VERSION ""

NS_ :

BS_:

BU_:

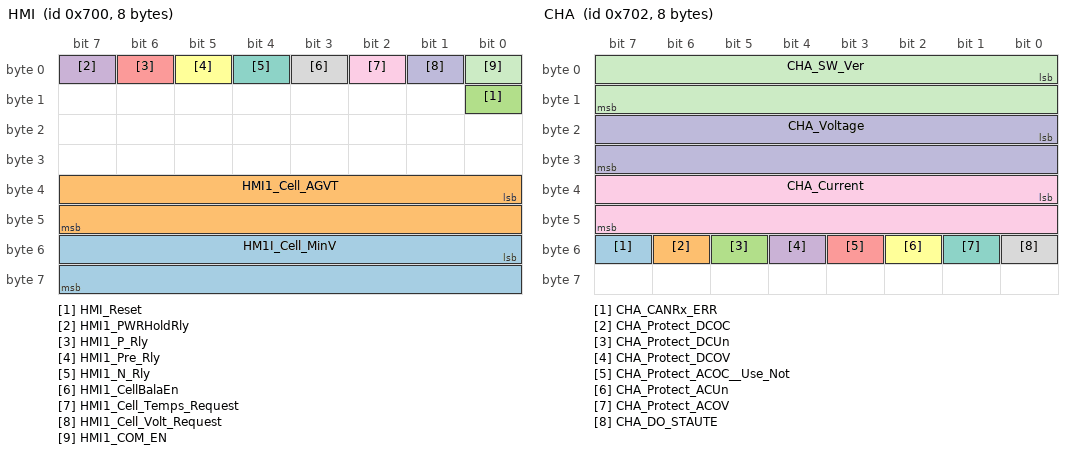
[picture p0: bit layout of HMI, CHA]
BO_ 1792 HMI: 8 Vector__XXX
 SG_ HM1I_Cell_MinV : 48|16@1+ (0.001,0.0) [0.0|4.5] "V" Vector__XXX
 SG_ HMI1_Cell_AGVT : 32|16@1+ (0.1,0.0) [-30.0|100.0] "deg" Vector__XXX
 SG_ HMI_Reset : 8|1@1+ (1.0,0.0) [0.0|1.0] "F" Vector__XXX
 SG_ HMI1_PWRHoldRly : 7|1@1+ (1.0,0.0) [0.0|1.0] "F" Vector__XXX
 SG_ HMI1_P_Rly : 6|1@1+ (1.0,0.0) [0.0|1.0] "F" Vector__XXX
 SG_ HMI1_Pre_Rly : 5|1@1+ (1.0,0.0) [0.0|1.0] "F" Vector__XXX
 SG_ HMI1_N_Rly : 4|1@1+ (1.0,0.0) [0.0|1.0] "F" Vector__XXX
 SG_ HMI1_CellBalaEn : 3|1@1+ (1.0,0.0) [0.0|1.0] "F" Vector__XXX
 SG_ HMI1_Cell_Temps_Request : 2|1@1+ (1.0,0.0) [0.0|1.0] "F" Vector__XXX
 SG_ HMI1_Cell_Volt_Request : 1|1@1+ (1.0,0.0) [0.0|1.0] "F" Vector__XXX
 SG_ HMI1_COM_EN : 0|1@1+ (1.0,0.0) [0.0|1.0] "F" Vector__XXX

BO_ 1794 CHA: 8 Vector__XXX
 SG_ CHA_CANRx_ERR : 55|1@1+ (1.0,0.0) [0.0|1.0] "F" Vector__XXX
 SG_ CHA_Protect_DCOC : 54|1@1+ (1.0,0.0) [0.0|1.0] "F" Vector__XXX
 SG_ CHA_Protect_DCUn : 53|1@1+ (1.0,0.0) [0.0|1.0] "F" Vector__XXX
 SG_ CHA_Protect_DCOV : 52|1@1+ (1.0,0.0) [0.0|1.0] "F" Vector__XXX
 SG_ CHA_Protect_ACOC__Use_Not : 51|1@1+ (1.0,0.0) [0.0|1.0] "F" Vector__XXX
 SG_ CHA_Protect_ACUn : 50|1@1+ (1.0,0.0) [0.0|1.0] "F" Vector__XXX
 SG_ CHA_Protect_ACOV : 49|1@1+ (1.0,0.0) [0.0|1.0] "F" Vector__XXX
 SG_ CHA_DO_STAUTE : 48|1@1+ (1.0,0.0) [0.0|1.0] "F" Vector__XXX
 SG_ CHA_Current : 32|16@1- (0.1,0.0) [0.0|100.0] "A" Vector__XXX
 SG_ CHA_Voltage : 16|16@1+ (0.1,0.0) [40.0|100.0] "V" Vector__XXX
 SG_ CHA_SW_Ver : 0|16@1+ (0.1,0.0) [1.0|99.0] "VER" Vector__XXX

BO_ 1536 VCU_RE: 8 Vector__XXX
 SG_ Ifcu_BSAHldShutdown : 9|1@1+ (1.0,0.0) [0.0|1.0] "F" Vector__XXX
 SG_ Ifcu_BSAReset : 8|1@1+ (1.0,0.0) [0.0|1.0] "F" Vector__XXX

BO_ 812 CT_Sensor: 8 Vector__XXX
 SG_ CT_Sensor : 0|16@1+ (0.1,0.0) [-500.0|500.0] "A" Vector__XXX

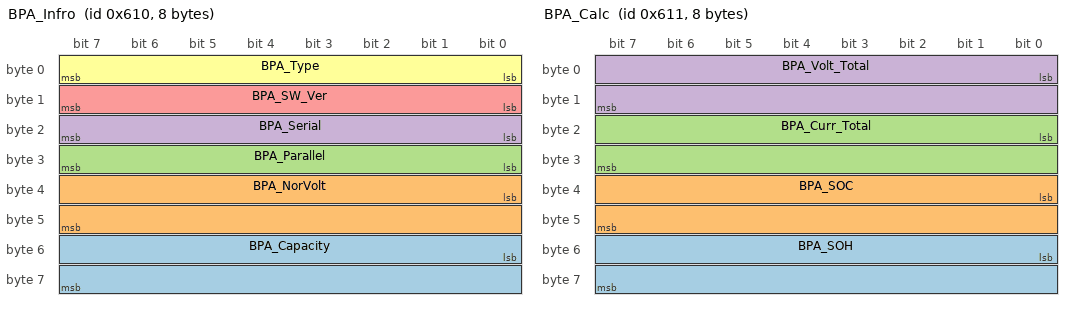
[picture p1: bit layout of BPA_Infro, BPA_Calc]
BO_ 1552 BPA_Infro: 8 Vector__XXX
 SG_ BPA_Capacity : 48|16@1+ (0.1,0.0) [0.0|500.0] "Ah" Vector__XXX
 SG_ BPA_NorVolt : 32|16@1+ (0.1,0.0) [0.0|900.0] "V" Vector__XXX
 SG_ BPA_Parallel : 24|8@1+ (1.0,0.0) [0.0|255.0] "P" Vector__XXX
 SG_ BPA_Serial : 16|8@1+ (1.0,0.0) [0.0|255.0] "S" Vector__XXX
 SG_ BPA_SW_Ver : 8|8@1+ (1.0,0.0) [0.0|255.0] "VER" Vector__XXX
 SG_ BPA_Type : 0|8@1+ (1.0,0.0) [0.0|255.0] "Type" Vector__XXX

BO_ 1553 BPA_Calc: 8 Vector__XXX
 SG_ BPA_SOH : 48|16@1+ (0.1,0.0) [0.0|100.0] "%" Vector__XXX
 SG_ BPA_SOC : 32|16@1+ (0.1,0.0) [0.0|100.0] "%" Vector__XXX
 SG_ BPA_Curr_Total : 16|16@1+ (0.1,0.0) [-500.0|500.0] "A" Vector__XXX
 SG_ BPA_Volt_Total : 0|16@1+ (0.1,0.0) [0.0|900.0] "V" Vector__XXX

BO_ 1554 BPA_State: 8 Vector__XXX
 SG_ Sys_CANCOMEnable : 60|1@1+ (1.0,0.0) [0.0|1.0] "F" Vector__XXX
 SG_ Sys_CellTempsOk : 59|1@1+ (1.0,0.0) [0.0|1.0] "F" Vector__XXX
 SG_ Sys_CellVoltOk : 58|1@1+ (1.0,0.0) [0.0|1.0] "F" Vector__XXX
 SG_ Sys_ISOSPICOMERR : 57|1@1+ (1.0,0.0) [0.0|1.0] "F" Vector__XXX
 SG_ Sys_CANCOMERR : 56|1@1+ (1.0,0.0) [0.0|1.0] "F" Vector__XXX
 SG_ Sys_HMIBalanceMode : 55|1@1+ (1.0,0.0) [0.0|1.0] "F" Vector__XXX
 SG_ Sys_HMICOMEnable : 54|1@1+ (1.0,0.0) [0.0|1.0] "F" Vector__XXX
 SG_ Sys_RlyERR : 53|1@1+ (1.0,0.0) [0.0|1.0] "F" Vector__XXX
 SG_ Sys_MSDERR : 52|1@1+ (1.0,0.0) [0.0|1.0] "F" Vector__XXX
 SG_ Sys_PwrHoldRlyDOStatus : 51|1@1+ (1.0,0.0) [0.0|1.0] "F" Vector__XXX
 SG_ Sys_PreRlyDOStatus : 50|1@1+ (1.0,0.0) [0.0|1.0] "F" Vector__XXX
 SG_ Sys_PRlyDOStatus : 49|1@1+ (1.0,0.0) [0.0|1.0] "F" Vector__XXX
 SG_ Sys_NRlyDOStatus : 48|1@1+ (1.0,0.0) [0.0|1.0] "F" Vector__XXX
 SG_ Sys_Fault : 47|1@1+ (1.0,0.0) [0.0|1.0] "F" Vector__XXX
 SG_ Sys_Aalarm : 46|1@1+ (1.0,0.0) [0.0|1.0] "F" Vector__XXX
 SG_ Sys_DisCharMode : 45|1@1+ (1.0,0.0) [0.0|1.0] "F" Vector__XXX
 SG_ Sys_BalanceEn : 44|1@1+ (1.0,0.0) [0.0|1.0] "F" Vector__XXX
 SG_ Sys_BalaMode : 43|1@1+ (1.0,0.0) [0.0|1.0] "F" Vector__XXX
 SG_ Sys_SysSocMode : 42|1@1+ (1.0,0.0) [0.0|1.0] "F" Vector__XXX
 SG_ Sys_CellInforRead : 41|1@1+ (1.0,0.0) [0.0|1.0] "F" Vector__XXX
 SG_ Sys_INITOK : 40|1@1+ (1.0,0.0) [0.0|1.0] "F" Vector__XXX
 SG_ Sys_SocSeqState : 38|2@1+ (1.0,0.0) [0.0|3.0] "s" Vector__XXX
 SG_ SyS_RlySeqState : 35|3@1+ (1.0,0.0) [0.0|7.0] "S" Vector__XXX
 SG_ Sys_SysSeqState : 32|3@1+ (1.0,0.0) [0.0|7.0] "S" Vector__XXX
 SG_ BPA_ChargerEn : 21|1@1+ (1.0,0.0) [0.0|1.0] "F" Vector__XXX
 SG_ BPA_MSD_AUX : 20|1@1+ (1.0,0.0) [0.0|1.0] "F" Vector__XXX
 SG_ BPA_PreChar_Rly : 19|1@1+ (1.0,0.0) [0.0|1.0] "F" Vector__XXX
 SG_ BPA_Pos_Rly : 18|1@1+ (1.0,0.0) [0.0|1.0] "F" Vector__XXX
 SG_ BPA_Neg_Rly : 17|1@1+ (1.0,0.0) [0.0|1.0] "F" Vector__XXX
 SG_ BPA_Balance : 16|1@1+ (1.0,0.0) [0.0|1.0] "F" Vector__XXX
 SG_ BPA_Protect_Status : 8|8@1+ (1.0,0.0) [0.0|5.0] "P" Vector__XXX
 SG_ BPA_Divice_Status : 0|8@1+ (1.0,0.0) [0.0|5.0] "S" Vector__XXX

BO_ 1555 BPA_ProtectState: 8 Vector__XXX
 SG_ BPA_Prtct_ISORESIS_Err : 44|1@1+ (1.0,0.0) [0|0] "F" Vector__XXX
 SG_ BPA_Prtct_CT_COM_Err : 43|1@1+ (1.0,0.0) [0|0] "F" Vector__XXX
 SG_ BPA_Prtct_CAN_COM_Err : 42|1@1+ (1.0,0.0) [0|0] "F" Vector__XXX
 SG_ BPA_Prtct_ISOSPI_Err : 41|1@1+ (1.0,0.0) [0|0] "F" Vector__XXX
 SG_ BPA_Prtct_Rly_Err : 40|1@1+ (1.0,0.0) [0|0] "F" Vector__XXX
 SG_ BPA_Prtct_Charger_UnBPAWR : 39|1@1+ (1.0,0.0) [0|0] "F" Vector__XXX
 SG_ BPA_Prtct_Discharger_UnBPAWR : 38|1@1+ (1.0,0.0) [0|0] "F" Vector__XXX
 SG_ BPA_Prtct_Cell_UnbalT : 37|1@1+ (1.0,0.0) [0|0] "F" Vector__XXX
 SG_ BPA_Prtct_Charger_Cell_UT : 36|1@1+ (1.0,0.0) [0|0] "F" Vector__XXX
 SG_ BPA_Prtct_DisCharger_Cell_UT : 35|1@1+ (1.0,0.0) [0|0] "F" Vector__XXX
 SG_ BPA_Prtct_Charger_Cell_OT : 34|1@1+ (1.0,0.0) [0|0] "F" Vector__XXX
 SG_ BPA_Prtct_DisCharger_Cell_OT : 33|1@1+ (1.0,0.0) [0|0] "F" Vector__XXX
 SG_ BPA_Prtct_Cell_UnbalV : 32|1@1+ (1.0,0.0) [0|0] "F" Vector__XXX
 SG_ BPA_Prtct_Cell_UV : 31|1@1+ (1.0,0.0) [0|0] "F" Vector__XXX
 SG_ BPA_Prtct_Cell_OV : 30|1@1+ (1.0,0.0) [0|0] "F" Vector__XXX
 SG_ BPA_Prtct_UV : 29|1@1+ (1.0,0.0) [0|0] "F" Vector__XXX
 SG_ BPA_Prtct_OV : 28|1@1+ (1.0,0.0) [0|0] "F" Vector__XXX
 SG_ BPA_Prtct_SOC_Un : 27|1@1+ (1.0,0.0) [0|0] "F" Vector__XXX
 SG_ BPA_Prtct_SOC_OV : 26|1@1+ (1.0,0.0) [0|0] "F" Vector__XXX
 SG_ BPA_Prtct_Chager_OC : 25|1@1+ (1.0,0.0) [0|0] "F" Vector__XXX
 SG_ BPA_Prtct_Dischager_OC : 24|1@1+ (1.0,0.0) [0|0] "F" Vector__XXX
 SG_ BPA_Wn_Charger_UnBPAWR : 15|1@1+ (1.0,0.0) [0|0] "F" Vector__XXX
 SG_ BPA_Wn_Discharger_UnBPAWR : 14|1@1+ (1.0,0.0) [0|0] "F" Vector__XXX
 SG_ BSA_Wn_Cell_UnbalT : 13|1@1+ (1.0,0.0) [0|0] "F" Vector__XXX
 SG_ BPA_Wn_Charger_Cell_UT : 12|1@1+ (1.0,0.0) [0|0] "F" Vector__XXX
 SG_ BPA_Wn_DisCharger_Cell_UT : 11|1@1+ (1.0,0.0) [0|0] "F" Vector__XXX
 SG_ BPA_Wn_Charger_Cell_OT : 10|1@1+ (1.0,0.0) [0|0] "F" Vector__XXX
 SG_ BPA_Wn_DisCharger_Cell_OT : 9|1@1+ (1.0,0.0) [0|0] "F" Vector__XXX
 SG_ BPA_Wn_Cell_UnbalV : 8|1@1+ (1.0,0.0) [0|0] "F" Vector__XXX
 SG_ BPA_Wn_Cell_UV : 7|1@1+ (1.0,0.0) [0|0] "F" Vector__XXX
 SG_ BPA_Wn_Cell_OV : 6|1@1+ (1.0,0.0) [0|0] "F" Vector__XXX
 SG_ BPA_Wn_UV : 5|1@1+ (1.0,0.0) [0|0] "F" Vector__XXX
 SG_ BPA_Wn_OV : 4|1@1+ (1.0,0.0) [0|0] "F" Vector__XXX
 SG_ BPA_Wn_SOC_UV : 3|1@1+ (1.0,0.0) [0|0] "F" Vector__XXX
 SG_ BPA_Wn_SOC_OV : 2|1@1+ (1.0,0.0) [0|0] "F" Vector__XXX
 SG_ BPA_Wn_Chager_OC : 1|1@1+ (1.0,0.0) [0|0] "F" Vector__XXX
 SG_ BPA_Wn_Dischager_OC : 0|1@1+ (1.0,0.0) [0|0] "F" Vector__XXX

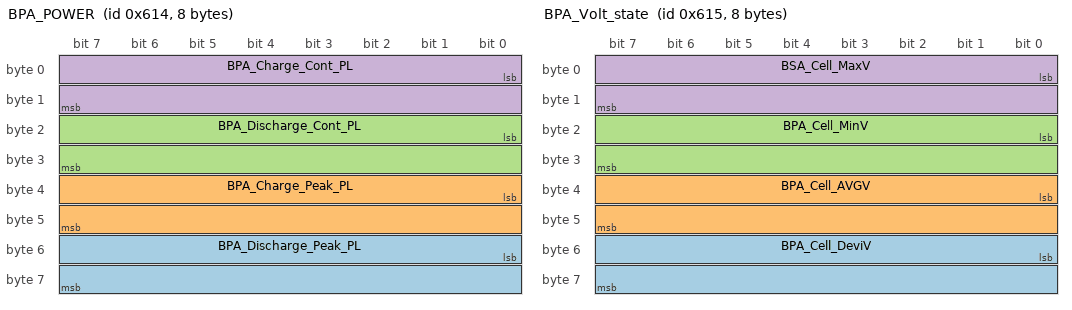
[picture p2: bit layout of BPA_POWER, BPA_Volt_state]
BO_ 1556 BPA_POWER: 8 Vector__XXX
 SG_ BPA_Discharge_Peak_PL : 48|16@1+ (0.1,0.0) [0.0|20.0] "kW" Vector__XXX
 SG_ BPA_Charge_Peak_PL : 32|16@1+ (0.1,0.0) [0.0|20.0] "kW" Vector__XXX
 SG_ BPA_Discharge_Cont_PL : 16|16@1+ (0.1,0.0) [0.0|20.0] "kW" Vector__XXX
 SG_ BPA_Charge_Cont_PL : 0|16@1+ (0.1,0.0) [0.0|20.0] "kW" Vector__XXX

BO_ 1557 BPA_Volt_state: 8 Vector__XXX
 SG_ BPA_Cell_DeviV : 48|16@1+ (1.0,0.0) [0.0|1000.0] "mV" Vector__XXX
 SG_ BPA_Cell_AVGV : 32|16@1+ (0.001,0.0) [0.0|4.5] "V" Vector__XXX
 SG_ BPA_Cell_MinV : 16|16@1+ (0.001,0.0) [0.0|4.5] "V" Vector__XXX
 SG_ BSA_Cell_MaxV : 0|16@1+ (0.001,0.0) [0.0|4.5] "V" Vector__XXX

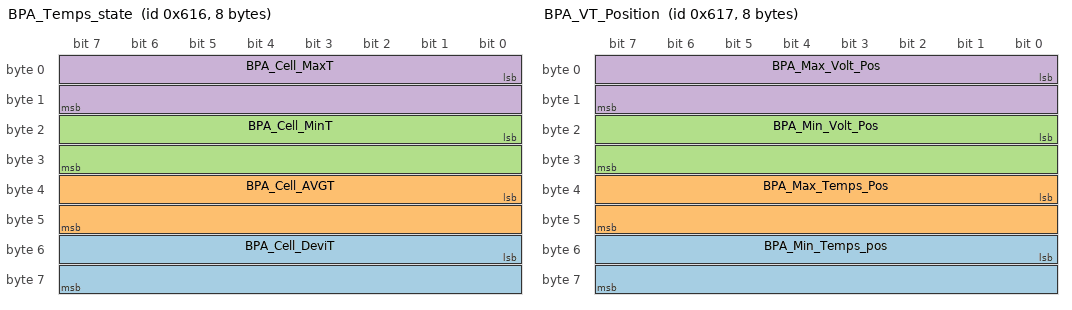
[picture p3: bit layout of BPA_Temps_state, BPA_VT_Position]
BO_ 1558 BPA_Temps_state: 8 Vector__XXX
 SG_ BPA_Cell_DeviT : 48|16@1+ (0.1,0.0) [0.0|100.0] "deg" Vector__XXX
 SG_ BPA_Cell_AVGT : 32|16@1+ (0.1,0.0) [-30.0|100.0] "deg" Vector__XXX
 SG_ BPA_Cell_MinT : 16|16@1+ (0.1,0.0) [-30.0|100.0] "deg" Vector__XXX
 SG_ BPA_Cell_MaxT : 0|16@1+ (0.1,0.0) [-30.0|100.0] "deg" Vector__XXX

BO_ 1559 BPA_VT_Position: 8 Vector__XXX
 SG_ BPA_Min_Temps_pos : 48|16@1+ (1.0,0.0) [0.0|200.0] "Pos" Vector__XXX
 SG_ BPA_Max_Temps_Pos : 32|16@1+ (1.0,0.0) [0.0|200.0] "Pos" Vector__XXX
 SG_ BPA_Min_Volt_Pos : 16|16@1+ (1.0,0.0) [0.0|200.0] "Pos" Vector__XXX
 SG_ BPA_Max_Volt_Pos : 0|16@1+ (1.0,0.0) [0.0|200.0] "Pos" Vector__XXX

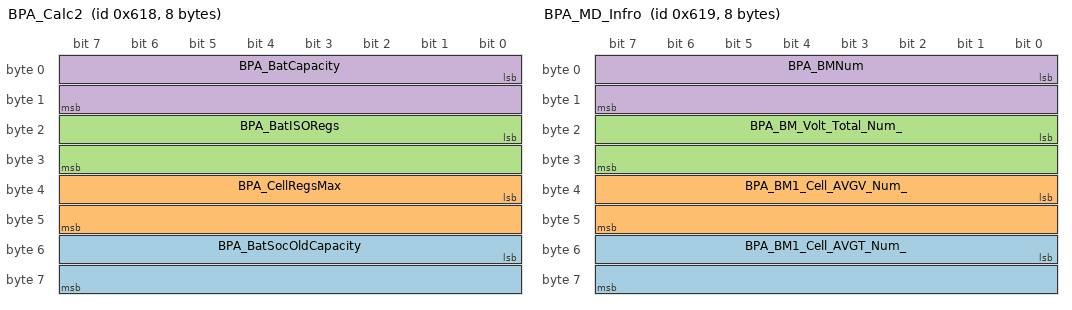
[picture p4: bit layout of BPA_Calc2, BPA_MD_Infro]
BO_ 1560 BPA_Calc2: 8 Vector__XXX
 SG_ BPA_BatSocOldCapacity : 48|16@1+ (0.1,0.0) [0.0|500.0] "Ah" Vector__XXX
 SG_ BPA_CellRegsMax : 32|16@1+ (0.1,0.0) [0.0|100.0] "mOhm" Vector__XXX
 SG_ BPA_BatISORegs : 16|16@1+ (0.1,0.0) [0.0|1000.0] "Mohm" Vector__XXX
 SG_ BPA_BatCapacity : 0|16@1+ (0.1,0.0) [-500.0|500.0] "Ah" Vector__XXX

BO_ 1561 BPA_MD_Infro: 8 Vector__XXX
 SG_ BPA_BM1_Cell_AVGT_Num_ : 48|16@1+ (0.1,0.0) [-30.0|100.0] "deg" Vector__XXX
 SG_ BPA_BM1_Cell_AVGV_Num_ : 32|16@1+ (0.001,0.0) [0.0|4.5] "V" Vector__XXX
 SG_ BPA_BM_Volt_Total_Num_ : 16|16@1+ (0.1,0.0) [0.0|100.0] "V" Vector__XXX
 SG_ BPA_BMNum : 0|16@1+ (0.1,0.0) [0.0|32.0] "V" Vector__XXX

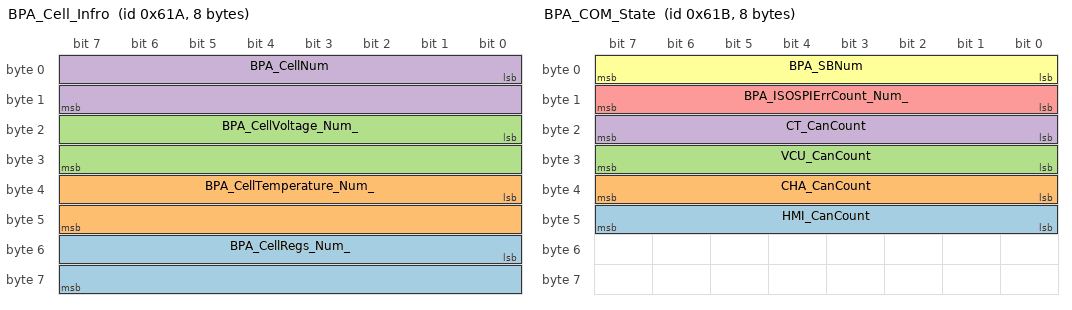
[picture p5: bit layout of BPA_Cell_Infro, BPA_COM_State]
BO_ 1562 BPA_Cell_Infro: 8 Vector__XXX
 SG_ BPA_CellRegs_Num_ : 48|16@1+ (0.1,0.0) [0.0|100.0] "mhom" Vector__XXX
 SG_ BPA_CellTemperature_Num_ : 32|16@1+ (0.1,0.0) [-30.0|100.0] "deg" Vector__XXX
 SG_ BPA_CellVoltage_Num_ : 16|16@1+ (0.001,0.0) [0.0|4.5] "V" Vector__XXX
 SG_ BPA_CellNum : 0|16@1+ (1.0,0.0) [0.0|400.0] "Num" Vector__XXX

BO_ 1563 BPA_COM_State: 8 Vector__XXX
 SG_ HMI_CanCount : 40|8@1+ (1.0,0.0) [0.0|250.0] "Cnt" Vector__XXX
 SG_ CHA_CanCount : 32|8@1+ (1.0,0.0) [0.0|250.0] "Cnt" Vector__XXX
 SG_ VCU_CanCount : 24|8@1+ (1.0,0.0) [0.0|250.0] "Cnt" Vector__XXX
 SG_ CT_CanCount : 16|8@1+ (1.0,0.0) [0.0|250.0] "Cnt" Vector__XXX
 SG_ BPA_ISOSPIErrCount_Num_ : 8|8@1+ (1.0,0.0) [0.0|250.0] "Cnt" Vector__XXX
 SG_ BPA_SBNum : 0|8@1+ (1.0,0.0) [0.0|30.0] "Num" Vector__XXX

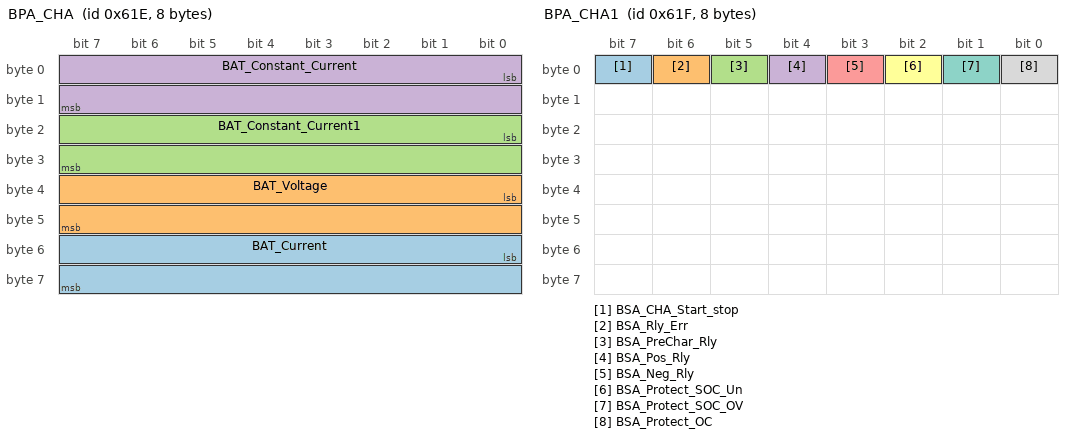
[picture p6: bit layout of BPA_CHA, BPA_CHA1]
BO_ 1566 BPA_CHA: 8 Vector__XXX
 SG_ BAT_Current : 48|16@1- (0.1,0.0) [0.0|100.0] "A" Vector__XXX
 SG_ BAT_Voltage : 32|16@1- (0.1,0.0) [0.0|100.0] "A" Vector__XXX
 SG_ BAT_Constant_Current1 : 16|16@1- (0.1,0.0) [0|100.0] "A" Vector__XXX
 SG_ BAT_Constant_Current : 0|16@1+ (0.1,0.0) [40.0|100.0] "V" Vector__XXX

BO_ 1567 BPA_CHA1: 8 Vector__XXX
 SG_ BSA_CHA_Start_stop : 7|1@1+ (1.0,0.0) [0.0|1.0] "F" Vector__XXX
 SG_ BSA_Rly_Err : 6|1@1+ (1.0,0.0) [0.0|1.0] "F" Vector__XXX
 SG_ BSA_PreChar_Rly : 5|1@1+ (1.0,0.0) [0.0|1.0] "F" Vector__XXX
 SG_ BSA_Pos_Rly : 4|1@1+ (1.0,0.0) [0.0|1.0] "F" Vector__XXX
 SG_ BSA_Neg_Rly : 3|1@1+ (1.0,0.0) [0.0|1.0] "F" Vector__XXX
 SG_ BSA_Protect_SOC_Un : 2|1@1+ (1.0,0.0) [0.0|1.0] "F" Vector__XXX
 SG_ BSA_Protect_SOC_OV : 1|1@1+ (1.0,0.0) [0.0|1.0] "F" Vector__XXX
 SG_ BSA_Protect_OC : 0|1@1+ (1.0,0.0) [0.0|1.0] "F" Vector__XXX

CM_ SG_ 1792 HM1I_Cell_MinV "VCU CAN 통신 분리 된 상태에서
관리자가 BMS에게 강제로 셀 전압 균일화를 요청";
CM_ SG_ 1792 HMI1_Cell_AGVT "VCU CAN 통신 분리 된 상태에서
관리자가 BMS에게 셀 온도 데이터를 요청 ";
CM_ SG_ 1792 HMI_Reset "0X00=No Actioen
0x01=HMIReset";
CM_ SG_ 1792 HMI1_PWRHoldRly "0X00=Off;
0x01=On;";
CM_ SG_ 1792 HMI1_P_Rly "0X00=Off;
0x01=On;";
CM_ SG_ 1792 HMI1_Pre_Rly "0X00=Off;
0x01=On;";
CM_ SG_ 1792 HMI1_N_Rly "0X00=Off;
0x01=On;";
CM_ SG_ 1792 HMI1_CellBalaEn "0X00=No Actioen
0x01=HMIBalace";
CM_ SG_ 1792 HMI1_Cell_Temps_Request "VCU CAN 통신 분리 된 상태에서
관리자가 BMS에게 셀 전압 데이터를 요청 ";
CM_ SG_ 1792 HMI1_Cell_Volt_Request "VCU CAN 통신 분리 된 상태에서
관리자가 Battery System에게 셀 전압 데이터 요청 ";
CM_ SG_ 1792 HMI1_COM_EN "VCU CAN 통신 분리 된 상태에서 관리자가 Battery System 상태를 모니터링 하기 위한 모드 설정
0x0=No Action;
0x1=Reset;";
CM_ SG_ 1794 CHA_CANRx_ERR "0x0=NoAction
0x1= 배터리 시스템 - 충전기 간 CAN Communication Error";
CM_ SG_ 1794 CHA_Protect_DCOC "0x0=NoAction0;
0x1=BATE_UV;";
CM_ SG_ 1794 CHA_Protect_DCUn "0x0=NoAction; 
0x1=BATE_UV;";
CM_ SG_ 1794 CHA_Protect_DCOV "0x0=NoAction;
0x1=BATE_OV;";
CM_ SG_ 1794 CHA_Protect_ACOC__Use_Not "Use Not";
CM_ SG_ 1794 CHA_Protect_ACUn "0x0=No Action, 
0x1=AC_UV";
CM_ SG_ 1794 CHA_Protect_ACOV "0x0=No Action, 
0x1=AC_OV;";
CM_ SG_ 1794 CHA_DO_STAUTE "0x0=Rly_Off;
0x1=Rly_On;";
CM_ SG_ 1794 CHA_Current "충전기에서 측정하고 배터리 전류 ";
CM_ SG_ 1794 CHA_Voltage "충전기에서 측정하고 배터리 전압 ";
CM_ SG_ 1794 CHA_SW_Ver "충전기 프로그램 버전 ";
CM_ SG_ 1536 Ifcu_BSAHldShutdown "접점스위치 ON->OFF이후 VCU 가 BAT Shutdown 명령
0x0=NoAction;
0x1=PWR_OFF;";
CM_ SG_ 1536 Ifcu_BSAReset "VCU 가 BAT Protect 상태를 Reset 
0x0=NoAction
0x1=Reset;";
CM_ SG_ 812 CT_Sensor "유첨파일 참조";
CM_ SG_ 1552 BPA_Capacity "default(Battery System 전지용량), 300Ah";
CM_ SG_ 1552 BPA_NorVolt "default(Battery System 전지전압), 51.8V";
CM_ SG_ 1552 BPA_Parallel "default(Battery System 전지 병렬구성), 6";
CM_ SG_ 1552 BPA_Serial "default(Battery System 전지 직렬구성), 14";
CM_ SG_ 1552 BPA_SW_Ver "default(소프트웨어정보), 10";
CM_ SG_ 1552 BPA_Type "default(제품정보), 03";
CM_ SG_ 1553 BPA_SOH "Battery System 전지 상태값";
CM_ SG_ 1553 BPA_SOC "Battery System 충전량";
CM_ SG_ 1553 BPA_Curr_Total "Battery System 전류값";
CM_ SG_ 1553 BPA_Volt_Total "Battery System 전압값";
CM_ SG_ 1554 Sys_CANCOMEnable "0x0 : Disable
0x1 : Enable";
CM_ SG_ 1554 Sys_CellTempsOk "0x0 : Off;
0x1 : Ok";
CM_ SG_ 1554 Sys_CellVoltOk "0x0 : Off;
0x1 : Ok";
CM_ SG_ 1554 Sys_ISOSPICOMERR "0x0 : Nor;
0x1 : Fault";
CM_ SG_ 1554 Sys_CANCOMERR "0x0 : Nor;
0x1 : Fault";
CM_ SG_ 1554 Sys_HMIBalanceMode "0x0 : Disable
0x1 : Enable";
CM_ SG_ 1554 Sys_HMICOMEnable "0x0 : Disable
0x1 : Enable";
CM_ SG_ 1554 Sys_RlyERR "0x0 : Nor;
0x1 : Fault";
CM_ SG_ 1554 Sys_MSDERR "0x0 : Nor;
0x1 : Fault";
CM_ SG_ 1554 Sys_PwrHoldRlyDOStatus "0x0 : Off
0x1 : On";
CM_ SG_ 1554 Sys_PreRlyDOStatus "0x0 : Off
0x1 : On";
CM_ SG_ 1554 Sys_PRlyDOStatus "0x0 : Off
0x1 : On";
CM_ SG_ 1554 Sys_NRlyDOStatus "0x0 : Off
0x1 : On";
CM_ SG_ 1554 Sys_Fault "0x0 : Nor;
0x1 : Fault";
CM_ SG_ 1554 Sys_Aalarm "0x0 : Nor;
0x1 : Alarm";
CM_ SG_ 1554 Sys_DisCharMode "0x0 : Char
0x1 : DisChar";
CM_ SG_ 1554 Sys_BalanceEn "0x0 : Off
0x1 : On";
CM_ SG_ 1554 Sys_BalaMode "0x0 : Disable
0x1 : Enable";
CM_ SG_ 1554 Sys_SysSocMode "0x0 : Volt
0x1 : Curr";
CM_ SG_ 1554 Sys_CellInforRead "0x0 : Volt
0x1 : Curr";
CM_ SG_ 1554 Sys_INITOK "0x0 : Off;
0x1 : Ok";
CM_ SG_ 1554 Sys_SocSeqState "0x0: SOC_STATE_IDLE,
0x1: SOC_STATE_RUNNING,
0x2: SOC_STATE_Save,
0x3: SOC_STATE_CLEAR";
CM_ SG_ 1554 SyS_RlySeqState "0x0 : PrtctRly_INIT;
0x1 : PrtctRly_STANDBY;
0x2 : PrtctRly_Ready;
0x3 : PrtctRly_RuningON;
0x4 : PrtctRly_RuningOFF;
0x5 : PrtctRly_ProtectpOFF;
0x6 : PrtctRly_RLYProtect;
0x7 : PrtctRly_CLEAR;";
CM_ SG_ 1554 Sys_SysSeqState "0x0 : INIT;
0x1 : STANDBY;
0x2 : READY;
0x3 : RUNING;
0x4 : PROTECTER;
0x5 : DATALOG;
0x6 : ProtectHistory;
0x7 : MANUALMode;";
CM_ SG_ 1554 BPA_ChargerEn "0x00 : CharEnable 
0x01 : CharDisable";
CM_ SG_ 1554 BPA_MSD_AUX "0x0 : Close;
0x1 : Open;";
CM_ SG_ 1554 BPA_PreChar_Rly "0x0=Rly_Off;
0x1=Rly_On;";
CM_ SG_ 1554 BPA_Pos_Rly "0x0=Rly_Off;
0x1=Rly_On;";
CM_ SG_ 1554 BPA_Neg_Rly "0x0=Rly_Off;
0x1=Rly_On;";
CM_ SG_ 1554 BPA_Balance "0x00 : OFF
0x01 : ON";
CM_ SG_ 1554 BPA_Protect_Status "0x00 : Normal
0x01 : Warning
0x02 : Protection";
CM_ SG_ 1554 BPA_Divice_Status "0x00 : Init
0x01 : standby
0x02 : Charger mode
0x03 : Dischager mode ";
CM_ SG_ 1555 BPA_Prtct_ISORESIS_Err "0x0 : Nor;
0x1 : Fault";
CM_ SG_ 1555 BPA_Prtct_CT_COM_Err "0x0 : Nor;
0x1 : Fault";
CM_ SG_ 1555 BPA_Prtct_CAN_COM_Err "0x0 : Nor;
0x1 : Fault";
CM_ SG_ 1555 BPA_Prtct_ISOSPI_Err "0x0 : Nor;
0x1 : Fault";
CM_ SG_ 1555 BPA_Prtct_Rly_Err "0x0 : Nor;
0x1 : Fault";
CM_ SG_ 1555 BPA_Prtct_Charger_UnBPAWR "0x0 : Nor;
0x1 : Fault";
CM_ SG_ 1555 BPA_Prtct_Discharger_UnBPAWR "0x0 : Nor;
0x1 : Fault";
CM_ SG_ 1555 BPA_Prtct_Cell_UnbalT "0x0 : Nor;
0x1 : Fault";
CM_ SG_ 1555 BPA_Prtct_Charger_Cell_UT "0x0 : Nor;
0x1 : Fault";
CM_ SG_ 1555 BPA_Prtct_DisCharger_Cell_UT "0x0 : Nor;
0x1 : Fault";
CM_ SG_ 1555 BPA_Prtct_Charger_Cell_OT "0x0 : Nor;
0x1 : Fault";
CM_ SG_ 1555 BPA_Prtct_DisCharger_Cell_OT "0x0 : Nor;
0x1 : Fault";
CM_ SG_ 1555 BPA_Prtct_Cell_UnbalV "0x0 : Nor;
0x1 : Fault";
CM_ SG_ 1555 BPA_Prtct_Cell_UV "0x0 : Nor;
0x1 : Fault";
CM_ SG_ 1555 BPA_Prtct_Cell_OV "0x0 : Nor;
0x1 : Fault";
CM_ SG_ 1555 BPA_Prtct_UV "0x0 : Nor;
0x1 : Fault";
CM_ SG_ 1555 BPA_Prtct_OV "0x0 : Nor;
0x1 : Fault";
CM_ SG_ 1555 BPA_Prtct_SOC_Un "0x0 : Nor;
0x1 : Fault";
CM_ SG_ 1555 BPA_Prtct_SOC_OV "0x0 : Nor;
0x1 : Fault";
CM_ SG_ 1555 BPA_Prtct_Chager_OC "0x0 : Nor;
0x1 : Fault";
CM_ SG_ 1555 BPA_Prtct_Dischager_OC "0x0 : Nor;
0x1 : Fault";
CM_ SG_ 1555 BPA_Wn_Charger_UnBPAWR "0x0 : Nor;
0x1 : Alarm";
CM_ SG_ 1555 BPA_Wn_Discharger_UnBPAWR "0x0 : Nor;
0x1 : Alarm";
CM_ SG_ 1555 BSA_Wn_Cell_UnbalT "0x0 : Nor;
0x1 : Alarm";
CM_ SG_ 1555 BPA_Wn_Charger_Cell_UT "0x0 : Nor;
0x1 : Alarm";
CM_ SG_ 1555 BPA_Wn_DisCharger_Cell_UT "0x0 : Nor;
0x1 : Alarm";
CM_ SG_ 1555 BPA_Wn_Charger_Cell_OT "0x0 : Nor;
0x1 : Alarm";
CM_ SG_ 1555 BPA_Wn_DisCharger_Cell_OT "0x0 : Nor;
0x1 : Alarm";
CM_ SG_ 1555 BPA_Wn_Cell_UnbalV "0x0 : Nor;
0x1 : Alarm";
CM_ SG_ 1555 BPA_Wn_Cell_UV "0x0 : Nor;
0x1 : Alarm";
CM_ SG_ 1555 BPA_Wn_Cell_OV "0x0 : Nor;
0x1 : Alarm";
CM_ SG_ 1555 BPA_Wn_UV "0x0 : Nor;
0x1 : Alarm";
CM_ SG_ 1555 BPA_Wn_OV "0x0 : Nor;
0x1 : Alarm";
CM_ SG_ 1555 BPA_Wn_SOC_UV "0x0 : Nor;
0x1 : Alarm";
CM_ SG_ 1555 BPA_Wn_SOC_OV "0x0 : Nor;
0x1 : Alarm";
CM_ SG_ 1555 BPA_Wn_Chager_OC "0x0 : Nor;
0x1 : Alarm";
CM_ SG_ 1555 BPA_Wn_Dischager_OC "0x0 : Nor;
0x1 : Alarm";
CM_ SG_ 1556 BPA_Discharge_Peak_PL "Battery System Discharge Peak out Power limit";
CM_ SG_ 1556 BPA_Charge_Peak_PL "Battery System Charge Peak out Power limit";
CM_ SG_ 1556 BPA_Discharge_Cont_PL "Battery System Discharge continuity out Power limit";
CM_ SG_ 1556 BPA_Charge_Cont_PL "BATTERY System Charge continuity out Power limit";
CM_ SG_ 1557 BPA_Cell_DeviV "Battery System  Cell 전압편차값";
CM_ SG_ 1557 BPA_Cell_AVGV "Battery System Cell 평균전압값";
CM_ SG_ 1557 BPA_Cell_MinV "Battery System Cell 최저전압값";
CM_ SG_ 1557 BSA_Cell_MaxV "Battery System Cell 최대전압값";
CM_ SG_ 1558 BPA_Cell_DeviT "Battery System Cell 온도편차값";
CM_ SG_ 1558 BPA_Cell_AVGT "Battery System Cell 평균온도값";
CM_ SG_ 1558 BPA_Cell_MinT "Battery System Cell 최저온도값";
CM_ SG_ 1558 BPA_Cell_MaxT "Battery System Cell 최대온도값";
CM_ SG_ 1559 BPA_Min_Temps_pos "Battery System 최소온도값";
CM_ SG_ 1559 BPA_Max_Temps_Pos "Battery System 최대온도값";
CM_ SG_ 1559 BPA_Min_Volt_Pos "Battery System 최소전압값";
CM_ SG_ 1559 BPA_Max_Volt_Pos "Battery System 최대전압값";
CM_ SG_ 1560 BPA_BatSocOldCapacity "NVRAM 저장 할 것 ";
CM_ SG_ 1561 BPA_BM1_Cell_AVGT_Num_ "Battery Module1 Cell 평균온도값";
CM_ SG_ 1561 BPA_BM1_Cell_AVGV_Num_ "Battery Module1 Cell 평균전압값";
CM_ SG_ 1561 BPA_BM_Volt_Total_Num_ "Battery Module1 전압값";
CM_ SG_ 1561 BPA_BMNum "Battery Module1 전압값";
CM_ SG_ 1562 BPA_CellRegs_Num_ "CellNum에 해당하는 셀 내부저항";
CM_ SG_ 1562 BPA_CellTemperature_Num_ "CellNum에 해당하는 셀 온도";
CM_ SG_ 1562 BPA_CellVoltage_Num_ "CellNum에 해당하는 셀 전압";
CM_ SG_ 1562 BPA_CellNum "전압 대상 셀 번호 (0~384)";
CM_ SG_ 1563 HMI_CanCount "HMI(출하검사) CAN 메시지 수신 시마다 내부 Count 변수 증가 (디버깅용)";
CM_ SG_ 1563 CHA_CanCount "충전기 CAN 메시지 수신 시마다 내부 Count 변수 증가 (디버깅용)";
CM_ SG_ 1563 VCU_CanCount "VCU CAN 메시지 수신 시마다 내부 Count 변수 증가 (디버깅용)";
CM_ SG_ 1563 CT_CanCount "CT 센서 CAN 메시지 수신 시마다 내부 Count 변수 증가 (디버깅용)";
CM_ SG_ 1563 BPA_ISOSPIErrCount_Num_ "CellNum에 해당하는 Slave BMS ISOSPIErrCount 값 ";
CM_ SG_ 1563 BPA_SBNum "ISOSPIErrCount 대상 Slave BMS번호 (0~384)";
CM_ SG_ 1566 BAT_Current "Current value of the battery pack measured by the BMS";
CM_ SG_ 1566 BAT_Voltage "Voltage value of the battery pack measured by the BMS";
CM_ SG_ 1566 BAT_Constant_Current1 "Constant Current  Charging Request from Battery System to Charger";
CM_ SG_ 1566 BAT_Constant_Current "Constant Voltage Charging Request from Battery System to Charger";
CM_ SG_ 1567 BSA_CHA_Start_stop "0x0 : CharStop
0x1 : CharStart";
CM_ SG_ 1567 BSA_Rly_Err "0x0 : Off
0x1 : On";
CM_ SG_ 1567 BSA_PreChar_Rly "0x0 : Off
0x1 : On";
CM_ SG_ 1567 BSA_Pos_Rly "0x0 : Off
0x1 : On";
CM_ SG_ 1567 BSA_Neg_Rly "0x0 : Nor;
0x1 : Fault";
CM_ SG_ 1567 BSA_Protect_SOC_Un "0x0 : Nor;
0x1 : Fault";
CM_ SG_ 1567 BSA_Protect_SOC_OV "0x0 : Nor;
0x1 : Fault";
CM_ SG_ 1567 BSA_Protect_OC "0x0 : Nor;
0x1 : Fault";
BA_DEF_ BO_  "GenMsgCycleTime" INT 0 65535;
BA_DEF_ SG_  "GenSigStartValue" FLOAT 0 100000000000;
BA_DEF_DEF_  "GenMsgCycleTime" 0;
BA_DEF_DEF_  "GenSigStartValue" 0;
BA_ "GenMsgCycleTime" BO_ 1792 100;
BA_ "GenMsgCycleTime" BO_ 1794 1000;
BA_ "GenMsgCycleTime" BO_ 1536 100;
BA_ "GenMsgCycleTime" BO_ 812 10;
BA_ "GenMsgCycleTime" BO_ 1552 1000;
BA_ "GenMsgCycleTime" BO_ 1553 10;
BA_ "GenMsgCycleTime" BO_ 1554 10;
BA_ "GenMsgCycleTime" BO_ 1555 100;
BA_ "GenMsgCycleTime" BO_ 1556 100;
BA_ "GenMsgCycleTime" BO_ 1557 100;
BA_ "GenMsgCycleTime" BO_ 1558 100;
BA_ "GenMsgCycleTime" BO_ 1559 100;
BA_ "GenMsgCycleTime" BO_ 1560 100;
BA_ "GenMsgCycleTime" BO_ 1561 100;
BA_ "GenMsgCycleTime" BO_ 1562 100;
BA_ "GenMsgCycleTime" BO_ 1563 100;
BA_ "GenMsgCycleTime" BO_ 1566 1000;
BA_ "GenMsgCycleTime" BO_ 1567 1000;
